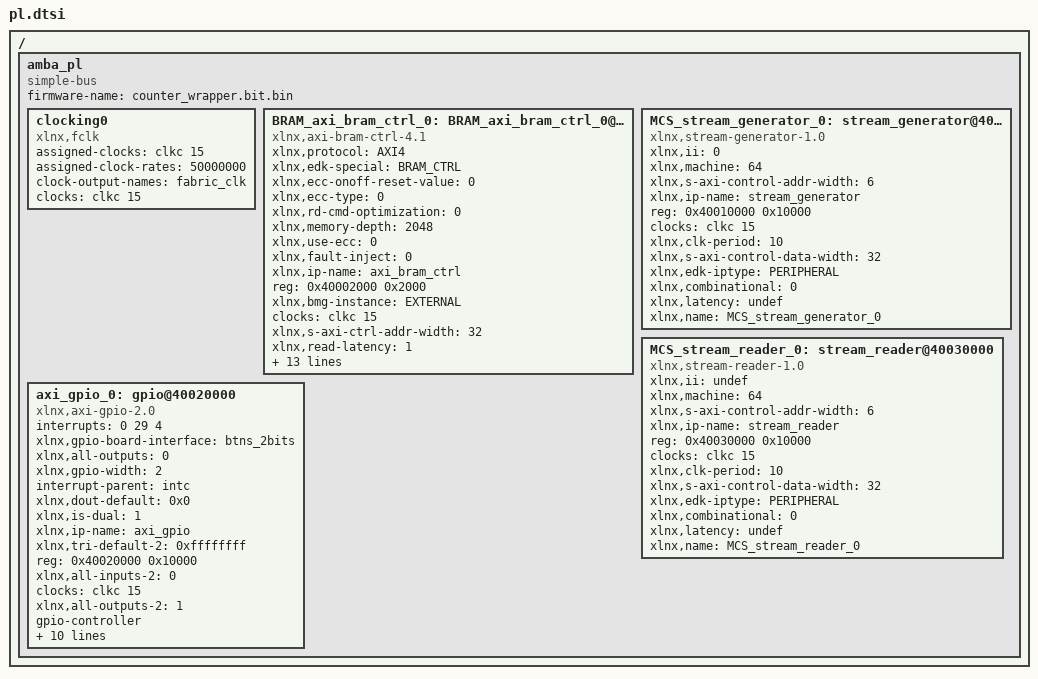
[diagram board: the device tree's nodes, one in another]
/ {
	amba_pl: amba_pl {
		ranges;
		compatible = "simple-bus";
		#address-cells = <1>;
		#size-cells = <1>;
		firmware-name = "counter_wrapper.bit.bin";
		clocking0: clocking0 {
			compatible = "xlnx,fclk";
			assigned-clocks = <&clkc 15>;
			assigned-clock-rates = <50000000>;
			#clock-cells = <0>;
			clock-output-names = "fabric_clk";
			clocks = <&clkc 15>;
		};
		BRAM_axi_bram_ctrl_0: BRAM_axi_bram_ctrl_0@40002000 {
			xlnx,protocol = "AXI4";
			xlnx,edk-special = "BRAM_CTRL";
			compatible = "xlnx,axi-bram-ctrl-4.1" , "xlnx,axi-bram-ctrl";
			xlnx,ecc-onoff-reset-value = <0>;
			xlnx,ecc-type = <0>;
			xlnx,rd-cmd-optimization = <0>;
			xlnx,memory-depth = <2048>;
			xlnx,use-ecc = <0>;
			xlnx,fault-inject = <0>;
			xlnx,ip-name = "axi_bram_ctrl";
			reg = <0x40002000 0x2000>;
			xlnx,bmg-instance = "EXTERNAL";
			clocks = <&clkc 15>;
			xlnx,s-axi-ctrl-addr-width = <32>;
			xlnx,read-latency = <1>;
			xlnx,id-width = <0>;
			xlnx,s-axi-supports-narrow-burst = <0>;
			xlnx,supports-narrow-burst = <0>;
			xlnx,single-port-bram = <0>;
			xlnx,ecc = <0>;
			xlnx,edk-iptype = "PERIPHERAL";
			status = "okay";
			clock-names = "s_axi_aclk";
			xlnx,data-width = <32>;
			xlnx,bram-addr-width = <11>;
			xlnx,bram-inst-mode = "EXTERNAL";
			xlnx,s-axi-ctrl-data-width = <32>;
			xlnx,mem-depth = <2048>;
			xlnx,s-axi-id-width = <1>;
			xlnx,name = "BRAM_axi_bram_ctrl_0";
		};
		MCS_stream_generator_0: stream_generator@40010000 {
			compatible = "xlnx,stream-generator-1.0";
			xlnx,ii = <0>;
			xlnx,machine = <64>;
			xlnx,s-axi-control-addr-width = <6>;
			xlnx,ip-name = "stream_generator";
			reg = <0x40010000 0x10000>;
			clocks = <&clkc 15>;
			xlnx,clk-period = <10>;
			xlnx,s-axi-control-data-width = <32>;
			xlnx,edk-iptype = "PERIPHERAL";
			status = "okay";
			clock-names = "ap_clk";
			xlnx,combinational = <0>;
			xlnx,latency = "undef";
			xlnx,name = "MCS_stream_generator_0";
		};
		MCS_stream_reader_0: stream_reader@40030000 {
			compatible = "xlnx,stream-reader-1.0";
			xlnx,ii = "undef";
			xlnx,machine = <64>;
			xlnx,s-axi-control-addr-width = <6>;
			xlnx,ip-name = "stream_reader";
			reg = <0x40030000 0x10000>;
			clocks = <&clkc 15>;
			xlnx,clk-period = <10>;
			xlnx,s-axi-control-data-width = <32>;
			xlnx,edk-iptype = "PERIPHERAL";
			status = "okay";
			clock-names = "ap_clk";
			xlnx,combinational = <0>;
			xlnx,latency = "undef";
			xlnx,name = "MCS_stream_reader_0";
		};
		axi_gpio_0: gpio@40020000 {
			#interrupt-cells = <2>;
			interrupts = < 0 29 4 >;
			xlnx,gpio-board-interface = "btns_2bits";
			compatible = "xlnx,axi-gpio-2.0" , "xlnx,xps-gpio-1.00.a";
			xlnx,all-outputs = <0>;
			#gpio-cells = <2>;
			xlnx,gpio-width = <2>;
			interrupt-parent = <&intc>;
			xlnx,dout-default = <0x0>;
			xlnx,is-dual = <1>;
			xlnx,ip-name = "axi_gpio";
			xlnx,tri-default-2 = <0xffffffff>;
			reg = <0x40020000 0x10000>;
			xlnx,all-inputs-2 = <0>;
			clocks = <&clkc 15>;
			xlnx,all-outputs-2 = <1>;
			gpio-controller;
			device_type = "gpio";
			xlnx,interrupt-present = <1>;
			xlnx,gpio2-board-interface = "Custom";
			xlnx,edk-iptype = "PERIPHERAL";
			xlnx,dout-default-2 = <0x0>;
			status = "okay";
			xlnx,gpio2-width = <3>;
			clock-names = "s_axi_aclk";
			xlnx,use-board-flow;
			interrupt-controller;
			interrupt-names = "ip2intc_irpt";
			xlnx,tri-default = <0xffffffff>;
			xlnx,name = "axi_gpio_0";
			xlnx,all-inputs = <1>;
		};
	};
};
